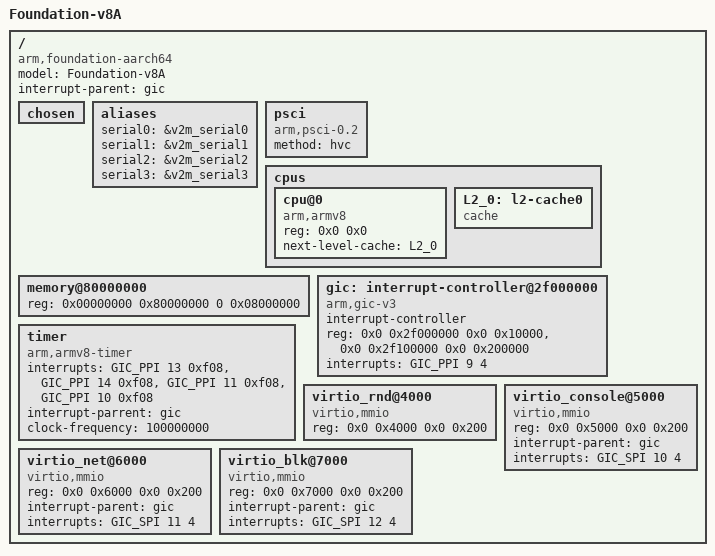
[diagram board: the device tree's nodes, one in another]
/*
 * ARM Ltd.
 *
 * ARMv8 Foundation model DTS (GICv3 configuration)
 */
/dts-v1/;

#include <dt-bindings/interrupt-controller/arm-gic.h>

/ {
	model = "Foundation-v8A";
	compatible = "arm,foundation-aarch64", "arm,vexpress";
	interrupt-parent = <&gic>;
	#address-cells = <2>;
	#size-cells = <2>;

	chosen { };

	aliases {
		serial0 = &v2m_serial0;
		serial1 = &v2m_serial1;
		serial2 = &v2m_serial2;
		serial3 = &v2m_serial3;
	};

	psci {
		compatible = "arm,psci-0.2";
		method="hvc";
	};

	cpus {
		#address-cells = <2>;
		#size-cells = <0>;

		cpu@0 {
			device_type = "cpu";
			compatible = "arm,armv8";
			reg = <0x0 0x0>;
			//enable-method = "spin-table";
			//cpu-release-addr = <0x0 0x8000fff8>;
			next-level-cache = <&L2_0>;
		};

		// TODO uncomment when SMP is implemented in hyp
		/*
		cpu@1 {
			device_type = "cpu";
			compatible = "arm,armv8";
			reg = <0x0 0x1>;
			//enable-method = "spin-table";
			//cpu-release-addr = <0x0 0x8000fff8>;
			next-level-cache = <&L2_0>;
		};
		*/
		L2_0: l2-cache0 {
			compatible = "cache";
		};
	};

	/* 128 MB of memory from address 0x80000000 to 0x88000000 (64bit) */
	memory@80000000 {
		device_type = "memory";
		reg = <0x00000000 0x80000000 0  0x08000000>;
	};

	gic: interrupt-controller@2f000000 {
		compatible = "arm,gic-v3";
		#interrupt-cells = <3>;
		#size-cells = <2>;
		interrupt-controller;
		reg =	<0x0 0x2f000000 0x0 0x10000>,	/* Distributor */
			<0x0 0x2f100000 0x0 0x200000>;	/* Redistributor */
		interrupts = <GIC_PPI 9 4>;		/* IRQ 25, edge triggered */
	};

/*
	uart0: uart@0x3f8 {
		compatible = "ns16550a";
		reg = <0x0 0x3f8 0x0 0x200>;
		clock-frequency = <1843200>;
		interrupts = <1 4 4>;
		interrupt-parrent = <&gic>;
	}
*/

	timer {
		compatible = "arm,armv8-timer";
		interrupts = <GIC_PPI 13 0xf08>,	/* Secure Physical Timer */
			     <GIC_PPI 14 0xf08>,	/* Non-secure Physical Timer*/
			     <GIC_PPI 11 0xf08>,	/* Virtual Timer */
			     <GIC_PPI 10 0xf08>;	/* EL2 Timer */
		interrupt-parrent = <&gic>;
		clock-frequency = <100000000>;
	};

	virtio_rnd@4000 {
		compatible = "virtio,mmio";
		reg = <0x0 0x4000 0x0 0x200>;
	};

	virtio_console@5000 {
		compatible = "virtio,mmio";
		reg = <0x0 0x5000 0x0 0x200>;
		interrupt-parent=<&gic>;
		interrupts = <GIC_SPI 10 4>;
	};

	virtio_net@6000 {
		compatible = "virtio,mmio";
		reg = <0x0 0x6000 0x0 0x200>;
		interrupt-parent=<&gic>;
		interrupts = <GIC_SPI 11 4>;
	};

	virtio_blk@7000 {
		compatible = "virtio,mmio";
		reg = <0x0 0x7000 0x0 0x200>;
		interrupt-parent=<&gic>;
		interrupts = <GIC_SPI 12 4>;
	};
};
